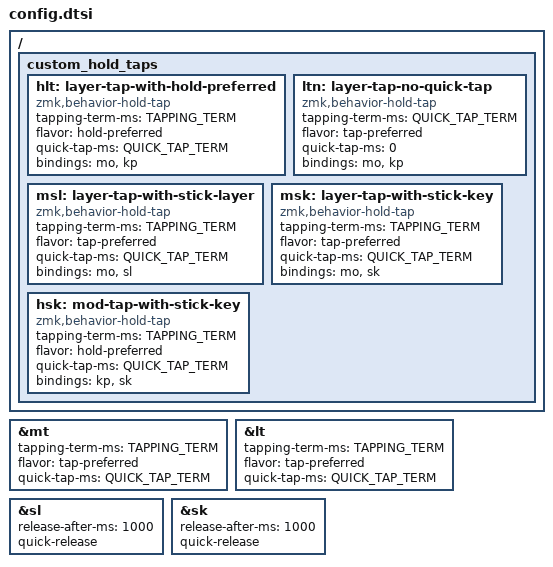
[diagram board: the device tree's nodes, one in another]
/*
 *
 * Copyright (c) 2022 Rafael Romão
 * SPDX-License-Identifier: MIT
 *
 */

#define ALPHA1 0

#define CAMEL_CASE 1
#define SNAKE_CASE 2
#define CONST_CASE 3
#define KEBAB_CASE 4
#define SLASH_CASE 5
#define SPACING 6
#define CASE_A1 7
#define CPLK_A1 8

#define ALPHA2 9

#define LOWER 10
#define RAISE 11

#define SEN_CASE 12
#define SEN_EXT 13

#define CCEDIL 14
#define SHIFT_A2 15
#define CASE_A2 16
#define CASE_CCEDIL 17

#define SHORTCUTS 18
#define SHORTS_EXT_1 19
#define SHORTS_EXT_2 20

#define CUSTOM 21

#define PLAIN1 22
#define PLAIN2 23
#define SFT_PLAIN2 24

#define NAV 25

#define LOW_CP 26
#define RAI_CP 27

#define MEDIA 28

#define FUN 29
#define SMART 30

#define NAV_F 31


#define COMBO_TERM 30
#define TAPPING_TERM 250
#define QUICK_TAP_TERM 150
#define ADAPTIVE_KEY_TIMEOUT 2000

/*                KEY POSITIONS

  ╭─────────────────────╮ ╭─────────────────────╮
  │ LTP LTR LTM LTI LTC │ │ RTC RTI RTM RTR RTP │
  │ LHP LHR LHM LHI LHC │ │ RHC RHI RHM RHR RHP │
  │ LBP LBR LBM LBI LBC │ │ RBC RBI RBM RBR RBP │
  ╰───────╮ L2  L1  L0  │ │ R0  R1  R2  ╭───────╯
          ╰─────────────╯ ╰─────────────╯ 
  ╭─────────────────────╮ ╭─────────────────────╮
  │  0   1   2   3   4  │ │   5   6   7   8   9 │
  │ 10  11  12  13  14  │ │  15  16  17  18  19 │
  │ 20  21  22  23  24  │ │  25  26  27  28  29 │
  ╰──────╮  30  31  32  │ │  33  34  35 ╭───────╯
         ╰──────────────╯ ╰─────────────╯

*/

#define LTP 0   // left-top row
#define LTR 1
#define LTM 2
#define LTI 3
#define LTC 4  

#define RTC 5   // right-top row
#define RTI 6
#define RTM 7
#define RTR 8
#define RTP 9

#define LHP 10  // left-middle row
#define LHR 11
#define LHM 12
#define LHI 13
#define LHC 14

#define RHC 15  // right-middle row
#define RHI 16
#define RHM 17
#define RHR 18
#define RHP 19

#define LBP 20  // left-bottom row
#define LBR 21
#define LBM 22
#define LBI 23
#define LBC 24

#define RBC 25  // right-bottom row
#define RBI 26
#define RBM 27
#define RBR 28
#define RBP 29

#define L2  30  // left thumb keys
#define L1  31
#define L0  32

#define R0  33  // right thumb keys
#define R1  34
#define R2  35

&mt {
    tapping-term-ms = <TAPPING_TERM>;
    flavor = "tap-preferred";
    quick-tap-ms = <QUICK_TAP_TERM>;
};

&lt {
    tapping-term-ms = <TAPPING_TERM>;
    flavor = "tap-preferred";
    quick-tap-ms = <QUICK_TAP_TERM>;
};

&sl {
    release-after-ms = <1000>;
    quick-release;
};

&sk {
    release-after-ms = <1000>;
    quick-release;
};

/ {
    custom_hold_taps {

        hlt: layer-tap-with-hold-preferred {
            compatible = "zmk,behavior-hold-tap";
            #binding-cells = <2>;
            tapping-term-ms = <TAPPING_TERM>;
            flavor = "hold-preferred";
            quick-tap-ms = <QUICK_TAP_TERM>;
            bindings = <&mo>, <&kp>;
        };

        ltn: layer-tap-no-quick-tap {
            compatible = "zmk,behavior-hold-tap";
            #binding-cells = <2>;
            tapping-term-ms = <QUICK_TAP_TERM>;
            flavor = "tap-preferred";
            quick-tap-ms = <0>;
            bindings = <&mo>, <&kp>;
        };

        msl: layer-tap-with-stick-layer {
            compatible = "zmk,behavior-hold-tap";
            #binding-cells = <2>;
            tapping-term-ms = <TAPPING_TERM>;
            flavor = "tap-preferred";
            quick-tap-ms = <QUICK_TAP_TERM>;
            bindings = <&mo>, <&sl>;
        };

        msk: layer-tap-with-stick-key {
            compatible = "zmk,behavior-hold-tap";
            #binding-cells = <2>;
            tapping-term-ms = <TAPPING_TERM>;
            flavor = "tap-preferred";
            quick-tap-ms = <QUICK_TAP_TERM>;
            bindings = <&mo>, <&sk>;
        };

        hsk: mod-tap-with-stick-key {
            compatible = "zmk,behavior-hold-tap";
            #binding-cells = <2>;
            tapping-term-ms = <TAPPING_TERM>;
            flavor = "hold-preferred";
            quick-tap-ms = <QUICK_TAP_TERM>;
            bindings = <&kp>, <&sk>;
        };

    };
};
